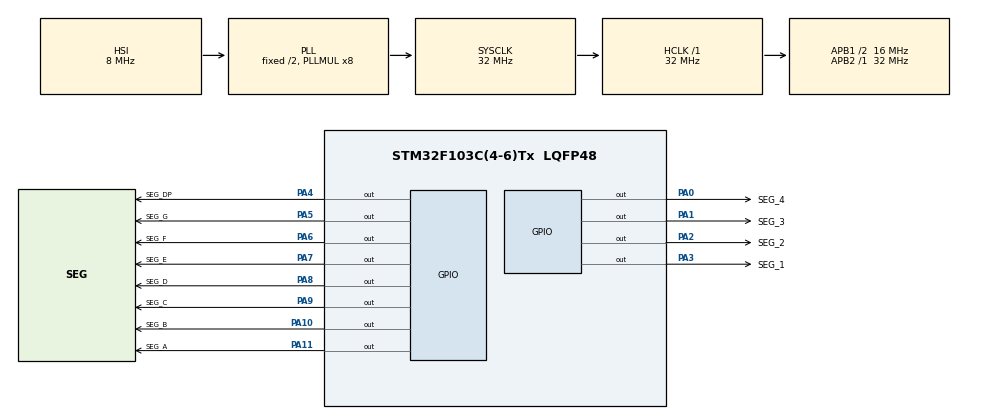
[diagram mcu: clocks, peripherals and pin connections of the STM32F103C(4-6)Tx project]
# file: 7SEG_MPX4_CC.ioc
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Mcu.Family=STM32F1
Mcu.Name=STM32F103C(4-6)Tx
Mcu.Package=LQFP48
NVIC.PriorityGroup=NVIC_PRIORITYGROUP_4
NVIC.TIM2_IRQn=true\:0\:0\:false\:false\:true\:true\:true\:true
PA0-WKUP.GPIO_Label=SEG_4
PA0-WKUP.Signal=GPIO_Output
PA1.GPIO_Label=SEG_3
PA1.Signal=GPIO_Output
PA10.GPIO_Label=SEG_B
PA10.Signal=GPIO_Output
PA11.GPIO_Label=SEG_A
PA11.Signal=GPIO_Output
PA2.GPIO_Label=SEG_2
PA2.Signal=GPIO_Output
PA3.GPIO_Label=SEG_1
PA3.Signal=GPIO_Output
PA4.GPIO_Label=SEG_DP
PA4.Signal=GPIO_Output
PA5.GPIO_Label=SEG_G
PA5.Signal=GPIO_Output
PA6.GPIO_Label=SEG_F
PA6.Signal=GPIO_Output
PA7.GPIO_Label=SEG_E
PA7.Signal=GPIO_Output
PA8.GPIO_Label=SEG_D
PA8.Signal=GPIO_Output
PA9.GPIO_Label=SEG_C
PA9.Signal=GPIO_Output
ProjectManager.HeapSize=0x200
ProjectManager.StackSize=0x400
ProjectManager.TargetToolchain=STM32CubeIDE
RCC.AHBFreq_Value=32000000
RCC.APB1CLKDivider=RCC_HCLK_DIV2
RCC.APB1Freq_Value=16000000
RCC.APB1TimFreq_Value=32000000
RCC.APB2Freq_Value=32000000
RCC.APB2TimFreq_Value=32000000
RCC.HCLKFreq_Value=32000000
RCC.PLLMUL=RCC_PLL_MUL8
RCC.SYSCLKFreq_VALUE=32000000
RCC.SYSCLKSource=RCC_SYSCLKSOURCE_PLLCLK
RCC.USBFreq_Value=32000000
TIM2.AutoReloadPreload=TIM_AUTORELOAD_PRELOAD_ENABLE
TIM2.Period=499
TIM2.Prescaler=63
VP_SYS_VS_ND.Mode=No_Debug
VP_TIM2_VS_ClockSourceINT.Mode=Internal
board=custom

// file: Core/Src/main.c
/* USER CODE BEGIN Header */
/**
  ******************************************************************************
  * @file           : main.c
  * @brief          : Main program body
  ******************************************************************************
  * @attention
  *
  * Copyright (c) 2023 STMicroelectronics.
  * All rights reserved.
  *
  * This software is licensed under terms that can be found in the LICENSE file
  * in the root directory of this software component.
  * If no LICENSE file comes with this software, it is provided AS-IS.
  *
  ******************************************************************************
  */
/* USER CODE END Header */
#include "main.h"
/* USER CODE BEGIN Includes */
#include "OS.h"
/* USER CODE END Includes */

TIM_HandleTypeDef htim2;

void SystemClock_Config(void);
static void MX_GPIO_Init(void);
static void MX_TIM2_Init(void);

int main(void)
{

  /* MCU Configuration--------------------------------------------------------*/

  /* Reset of all peripherals, Initializes the Flash interface and the Systick. */
  HAL_Init();

  /* Configure the system clock */
  SystemClock_Config();

  /* Initialize all configured peripherals */
  MX_GPIO_Init();
  MX_TIM2_Init();
  /* USER CODE BEGIN 2 */
  HAL_TIM_Base_Start_IT(&htim2);
  /* USER CODE END 2 */

  /* Infinite loop */
  while (1)
  {

    /* USER CODE BEGIN 3 */
	  OS();
  }
  /* USER CODE END 3 */
}

void SystemClock_Config(void)
{
  RCC_OscInitTypeDef RCC_OscInitStruct = {0};
  RCC_ClkInitTypeDef RCC_ClkInitStruct = {0};

  /** Initializes the RCC Oscillators according to the specified parameters
  * in the RCC_OscInitTypeDef structure.
  */
  RCC_OscInitStruct.OscillatorType = RCC_OSCILLATORTYPE_HSI;
  RCC_OscInitStruct.HSIState = RCC_HSI_ON;
  RCC_OscInitStruct.HSICalibrationValue = RCC_HSICALIBRATION_DEFAULT;
  RCC_OscInitStruct.PLL.PLLState = RCC_PLL_ON;
  RCC_OscInitStruct.PLL.PLLSource = RCC_PLLSOURCE_HSI_DIV2;
  RCC_OscInitStruct.PLL.PLLMUL = RCC_PLL_MUL8;
  if (HAL_RCC_OscConfig(&RCC_OscInitStruct) != HAL_OK)
  {
    Error_Handler();
  }

  /** Initializes the CPU, AHB and APB buses clocks
  */
  RCC_ClkInitStruct.ClockType = RCC_CLOCKTYPE_HCLK|RCC_CLOCKTYPE_SYSCLK
                              |RCC_CLOCKTYPE_PCLK1|RCC_CLOCKTYPE_PCLK2;
  RCC_ClkInitStruct.SYSCLKSource = RCC_SYSCLKSOURCE_PLLCLK;
  RCC_ClkInitStruct.AHBCLKDivider = RCC_SYSCLK_DIV1;
  RCC_ClkInitStruct.APB1CLKDivider = RCC_HCLK_DIV2;
  RCC_ClkInitStruct.APB2CLKDivider = RCC_HCLK_DIV1;

  if (HAL_RCC_ClockConfig(&RCC_ClkInitStruct, FLASH_LATENCY_1) != HAL_OK)
  {
    Error_Handler();
  }
}

static void MX_TIM2_Init(void)
{

  TIM_ClockConfigTypeDef sClockSourceConfig = {0};
  TIM_MasterConfigTypeDef sMasterConfig = {0};

  htim2.Instance = TIM2;
  htim2.Init.Prescaler = 63;
  htim2.Init.CounterMode = TIM_COUNTERMODE_UP;
  htim2.Init.Period = 499;
  htim2.Init.ClockDivision = TIM_CLOCKDIVISION_DIV1;
  htim2.Init.AutoReloadPreload = TIM_AUTORELOAD_PRELOAD_ENABLE;
  if (HAL_TIM_Base_Init(&htim2) != HAL_OK)
  {
    Error_Handler();
  }
  sClockSourceConfig.ClockSource = TIM_CLOCKSOURCE_INTERNAL;
  if (HAL_TIM_ConfigClockSource(&htim2, &sClockSourceConfig) != HAL_OK)
  {
    Error_Handler();
  }
  sMasterConfig.MasterOutputTrigger = TIM_TRGO_RESET;
  sMasterConfig.MasterSlaveMode = TIM_MASTERSLAVEMODE_DISABLE;
  if (HAL_TIMEx_MasterConfigSynchronization(&htim2, &sMasterConfig) != HAL_OK)
  {
    Error_Handler();
  }

}

static void MX_GPIO_Init(void)
{
  GPIO_InitTypeDef GPIO_InitStruct = {0};

  /* GPIO Ports Clock Enable */
  __HAL_RCC_GPIOA_CLK_ENABLE();

  /*Configure GPIO pin Output Level */
  HAL_GPIO_WritePin(GPIOA, SEG_4_Pin|SEG_3_Pin|SEG_2_Pin|SEG_1_Pin
                          |SEG_DP_Pin|SEG_G_Pin|SEG_F_Pin|SEG_E_Pin
                          |SEG_D_Pin|SEG_C_Pin|SEG_B_Pin|SEG_A_Pin, GPIO_PIN_RESET);

  /*Configure GPIO pins : SEG_4_Pin SEG_3_Pin SEG_2_Pin SEG_1_Pin
                           SEG_DP_Pin SEG_G_Pin SEG_F_Pin SEG_E_Pin
                           SEG_D_Pin SEG_C_Pin SEG_B_Pin SEG_A_Pin */
  GPIO_InitStruct.Pin = SEG_4_Pin|SEG_3_Pin|SEG_2_Pin|SEG_1_Pin
                          |SEG_DP_Pin|SEG_G_Pin|SEG_F_Pin|SEG_E_Pin
                          |SEG_D_Pin|SEG_C_Pin|SEG_B_Pin|SEG_A_Pin;
  GPIO_InitStruct.Mode = GPIO_MODE_OUTPUT_PP;
  GPIO_InitStruct.Pull = GPIO_NOPULL;
  GPIO_InitStruct.Speed = GPIO_SPEED_FREQ_LOW;
  HAL_GPIO_Init(GPIOA, &GPIO_InitStruct);

}

/* USER CODE BEGIN 4 */
void HAL_TIM_PeriodElapsedCallback(TIM_HandleTypeDef *htim)
{
	if (htim->Instance == TIM2)
	{

		LittleHeartFunc();
	}
}
/* USER CODE END 4 */

void Error_Handler(void)
{
  __disable_irq();
  while (1)
  {
  }
}
